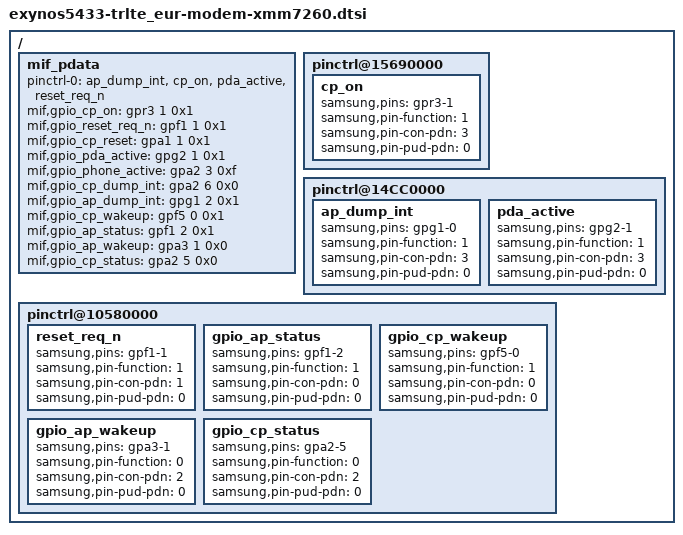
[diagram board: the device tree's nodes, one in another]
/*
 * SAMSUNG UNIVERSAL5430 board device tree source
 *
 * Copyright (c) 2013 Samsung Electronics Co., Ltd.
 *		http://www.samsung.com
 *
 * This program is free software; you can redistribute it and/or modify
 * it under the terms of the GNU General Public License version 2 as
 * published by the Free Software Foundation.
*/

#include "modem-xmm7260-pdata.dtsi"

/ {
	/* modem_interface_driver: Intel XMM7260 LTE Modem */
	mif_pdata {
		status = "okay";
		pinctrl-names = "default";
		pinctrl-0 = <&ap_dump_int &cp_on &pda_active &reset_req_n>;

		mif,gpio_cp_on = <&gpr3 1 0x1>;
		mif,gpio_reset_req_n = <&gpf1 1 0x1>;
		mif,gpio_cp_reset = <&gpa1 1 0x1>;
		mif,gpio_pda_active = <&gpg2 1 0x1>;
		mif,gpio_phone_active = <&gpa2 3 0xf>;
		mif,gpio_cp_dump_int = <&gpa2 6 0x0>;
		mif,gpio_ap_dump_int = <&gpg1 2 0x1>;

		mif,gpio_cp_wakeup = <&gpf5 0 0x1>;
		mif,gpio_ap_status = <&gpf1 2 0x1>;
		mif,gpio_ap_wakeup = <&gpa3 1 0x0>;
		mif,gpio_cp_status = <&gpa2 5 0x0>;
	}; /* end of mif_pdata */

	pinctrl@15690000 {
		cp_on: cp_on {
			samsung,pins = "gpr3-1";
			samsung,pin-function = <1>;
			samsung,pin-con-pdn = <3>;
			samsung,pin-pud-pdn = <0>;
		};
	};

	pinctrl@14CC0000 {
		ap_dump_int: ap_dump_int {
			samsung,pins = "gpg1-0";
			samsung,pin-function = <1>;
			samsung,pin-con-pdn = <3>;
			samsung,pin-pud-pdn = <0>;
		};
		pda_active: pda_active {
			samsung,pins = "gpg2-1";
			samsung,pin-function = <1>;
			samsung,pin-con-pdn = <3>;
			samsung,pin-pud-pdn = <0>;
		};
	};

	pinctrl@10580000 {
		reset_req_n: reset_req_n {
			samsung,pins = "gpf1-1";
			samsung,pin-function = <1>;
			samsung,pin-con-pdn = <1>;
			samsung,pin-pud-pdn = <0>;
		};
		gpio_ap_status: gpio_ap_status {
			samsung,pins = "gpf1-2";
			samsung,pin-function = <1>;
			samsung,pin-con-pdn = <0>;
			samsung,pin-pud-pdn = <0>;
		};
		gpio_cp_wakeup: gpio_cp_wakeup {
			samsung,pins = "gpf5-0";
			samsung,pin-function = <1>;
			samsung,pin-con-pdn = <0>;
			samsung,pin-pud-pdn = <0>;
		};
		gpio_ap_wakeup: gpio_ap_wakeup {
			samsung,pins = "gpa3-1";
			samsung,pin-function = <0>;
			samsung,pin-con-pdn = <2>;
			samsung,pin-pud-pdn = <0>;
		};
		gpio_cp_status: gpio_cp_status {
			samsung,pins = "gpa2-5";
			samsung,pin-function = <0>;
			samsung,pin-con-pdn = <2>;
			samsung,pin-pud-pdn = <0>;
		};
	};

};

